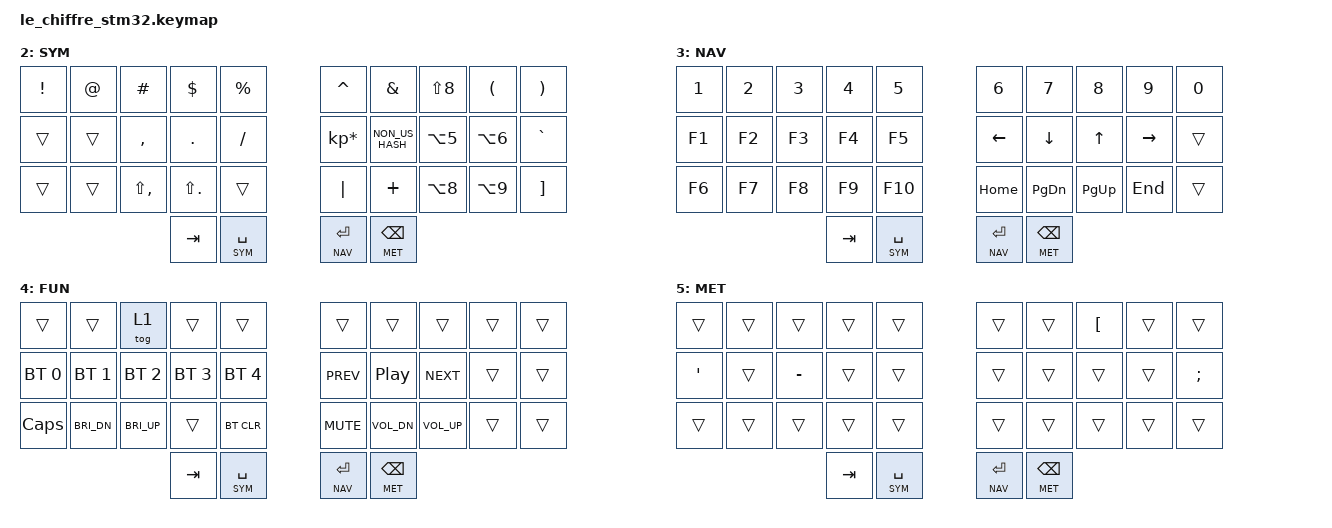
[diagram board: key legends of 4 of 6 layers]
/*
 * Copyright (c) 2020 The ZMK Contributors
 *
 * SPDX-License-Identifier: MIT
 */

#include <behaviors.dtsi>
#include <dt-bindings/zmk/keys.h>
#include <dt-bindings/zmk/bt.h>
#include <dt-bindings/zmk/outputs.h>


#define BAS 0
#define COL 1
#define SYM 2
#define NAV 3
#define FUN 4
#define MET 5

//&mt {
//  quick-tap-ms = <100>;
//  global-quick-tap;
//  flavor = "tap-preferred";
//  tapping-term-ms = <170>;
//};
&mt {
    flavor = "hold-preferred";
    tapping-term-ms = <150>;
};

&lt {
    flavor = "balanced";
    tapping-term-ms = <150>;
};

/ {
    behaviors {
        rot_kp: sensor_rotate_kp {
            compatible = "zmk,behavior-sensor-rotate-var";
            #sensor-binding-cells = <2>;
            bindings = <&kp>, <&kp>;
        };

        am: alpha_mods {
            compatible = "zmk,behavior-hold-tap";
            label = "ALPHA_MT";
            #binding-cells = <2>;
            tapping-term-ms = <200>;
            quick-tap-ms = <150>;
            flavor = "balanced";
            bindings = <&kp>, <&kp>;
        };
        as: alpha_shift {
            compatible = "zmk,behavior-hold-tap";
            label = "ALPHA_SFT";
            #binding-cells = <2>;
            tapping-term-ms = <200>;
            quick-tap-ms = <150>;
            flavor = "balanced";
            bindings = <&kp>, <&kp>;
        };

        // Easy alt-tab with alt+backspace thumb using mod-morphs
        bstab: backspace_tab {
            compatible = "zmk,behavior-mod-morph";
            label = "BSPC_TAB";
            #binding-cells = <0>;
            bindings = <&kp BSPC>, <&kp TAB>;
            mods = <LALT>;
        };
        lt_bspc: layer_tap_backspace_tab {
            compatible = "zmk,behavior-hold-tap";
            label = "LT_BT";
            #binding-cells = <2>;
            tapping-term-ms = <150>;
            flavor = "balanced";
            bindings = <&mo>, <&bstab>;
        };
    };

    cond_layers {
        compatible = "zmk,conditional-layers";
        // Define FUN layer as tri-state
        func_tristate {
            if-layers = <NAV SYM>;
            then-layer = <FUN>;
        };
    };

    combos {
        compatible = "zmk,combos";
        combo_esc {
            timeout-ms = <40>;
            key-positions = <1 2>;
            bindings = <&kp ESC>;
        };
        combo_dot {
            timeout-ms = <40>;
            key-positions = <12 13>;
            bindings = <&kp DOT>;
        };
        combo_comma {
            timeout-ms = <40>;
            key-positions = <11 12>;
            bindings = <&kp COMMA>;
        };
        
    };



    keymap {
        compatible = "zmk,keymap";
// ▄▄▄▄▄▄▄▄▄▄▄▄▄▄▄▄▄▄▄▄▄▄▄▄▄▄▄▄▄▄▄▄▄▄▄▄▄▄▄▄▄▄▄▄▄▄▄▄▄▄▄▄▄▄▄▄▄▄▄▄▄▄▄▄▄▄▄▄▄▄▄▄▄▄▄▄▄▄▄▄▄▄▄▄▄▄▄▄▄▄▄▄▄▄▄▄▄▄▄▄▄▄▄▄▄▄▄▄▄▄▄▄▄▄▄▄▄▄▄▄▄▄▄▄▄
        base {
            // ┏━━━━━━━━━━━━━━━━━━━━━━━━━━━━━━━━━━━━━━━┓
            label= "BAS"                              ;
            // ┗━━━━━━━━━━━━━━━━━━━━━━━━━━━━━━━━━━━━━━━┛
            bindings = <
                    // ╭─────────────┬─────────────┬─────────────┬─────────────┬─────────────╮   ╭─────────────┬─────────────┬─────────────┬─────────────┬─────────────╮
                            &kp X             &kp J      &kp O         &kp V        &kp Z             &kp MINUS    &kp G        &kp C         &kp L          &kp Y         
                    // ├─────────────┼─────────────┼─────────────┼─────────────┼─────────────┤   ├─────────────┼─────────────┼─────────────┼─────────────┼─────────────┤
                        &am LCTRL H   &am LGUI A    &am LALT E    &as LSHFT I   &kp U             &kp D          &as RSHFT T   &am RALT R   &am RGUI N    &am RCTRL S   
                    // ├─────────────┼─────────────┼─────────────┼─────────────┼─────────────┤   ├─────────────┼─────────────┼─────────────┼─────────────┼─────────────┤
                        &kp K         &kp Q         &kp SQT        &kp LBKT       &kp SEMI         &kp B          &kp P        &kp W           &kp M       &kp F      
                    // ╰─────────────┴─────────────┴─────────────┼─────────────┼─────────────┤   ├─────────────┼─────────────┼─────────────┴─────────────┴─────────────╯
                                                                &kp TAB       &lt SYM SPACE     &lt NAV RET   &lt MET BSPC
                    //                                           ╰─────────────┴─────────────╯   ╰─────────────┴─────────────╯
                                                                                            &kp C_PP

            >;          
            sensor-bindings = <&rot_kp C_VOL_UP C_VOL_DN>;
        };
        colemakdh {
            // ┏━━━━━━━━━━━━━━━━━━━━━━━━━━━━━━━━━━━━━━━┓
            label= "COL"                              ;
            // ┗━━━━━━━━━━━━━━━━━━━━━━━━━━━━━━━━━━━━━━━┛

            bindings = <
                // ╭─────────────┬─────────────┬─────────────┬─────────────┬─────────────╮   ╭─────────────┬─────────────┬─────────────┬─────────────┬─────────────╮
                        &kp Q        &kp W          &kp F        &kp P          &kp B              &kp J          &kp L        &kp U         &kp Y        &kp LS(COMMA)
                // ├─────────────┼─────────────┼─────────────┼─────────────┼─────────────┤   ├─────────────┼─────────────┼─────────────┼─────────────┼─────────────┤
                    &am LCTRL A   &am LGUI R    &am LALT S    &as LSHFT T   &kp G             &kp M          &as RSHFT N   &am RALT E   &am RGUI I    &am RCTRL O   
                // ├─────────────┼─────────────┼─────────────┼─────────────┼─────────────┤   ├─────────────┼─────────────┼─────────────┼─────────────┼─────────────┤
                        &kp Z         &kp X          &kp C          &kp D        &kp V            &kp K          &kp H       &kp COMMA    &kp PERIOD     &kp LS(N7)
                // ╰─────────────┴─────────────┴─────────────┼─────────────┼─────────────┤   ├─────────────┼─────────────┼─────────────┴─────────────┴─────────────╯
                                                            &kp TAB       &lt SYM SPACE     &lt NAV RET   &lt MET BSPC
                //                                           ╰─────────────┴─────────────╯   ╰─────────────┴─────────────╯
                                                                                        &kp C_PP


            >;               
            sensor-bindings = <&rot_kp C_VOL_UP C_VOL_DN>;
        };

        symbol_layer {
        // -----------------------------------------------------------------------------------------
        //  |  !  |  "  |  §  |  $  |  %  |   |  & |  /  |  (  |  )  |  =  |   
        //  |     |     |     |     |     |   |  * |  #  |  [  |  ]   |  <  |  
        //  |     |     |     |     |     |   | '  |  `  |  {  |  }   |  +  | 
        //         TAB | SYM / SPC  |            | NAV / ENT | MET / BKSP  
            label = "SYM";
            bindings = <
                // ╭─────────────┬─────────────┬─────────────┬─────────────┬─────────────╮   ╭─────────────┬─────────────┬─────────────┬─────────────┬─────────────╮
                        &kp EXCL      &kp AT        &kp HASH      &kp DLLR      &kp PRCNT         &kp CARET     &kp AMPS      &kp LS(N8)     &kp LPAR     &kp RPAR       
                // ├─────────────┼─────────────┼─────────────┼─────────────┼─────────────┤   ├─────────────┼─────────────┼─────────────┼─────────────┼─────────────┤
                        &trans        &trans        &kp COMMA        &kp DOT     &kp FSLH            &kp KP_MULTIPLY &kp NON_US_HASH &kp LA(N5) &kp LA(N6)  &kp GRAVE      
                // ├─────────────┼─────────────┼─────────────┼─────────────┼─────────────┤   ├─────────────┼─────────────┼─────────────┼─────────────┼─────────────┤
                        &trans        &trans        &kp LS(COMMA)     &kp LS(DOT)                &trans            &kp PIPE      &kp PLUS      &kp LA(N8)    &kp LA(N9)    &kp RBKT      
                // ╰─────────────┴─────────────┴─────────────┼─────────────┼─────────────┤   ├─────────────┼─────────────┼─────────────┴─────────────┴─────────────╯
                                                            &kp TAB       &lt SYM SPACE     &lt NAV RET   &lt MET BSPC
                //                                           ╰─────────────┴─────────────╯   ╰─────────────┴─────────────╯
            >;
        };

       navigation_layer {
        // -----------------------------------------------------------------------------------------
        // | |  1  |  2  |  3  |  4  |  5  |   |  6   |  7  | 8   |  9  |  0  |      |
        // | | F1  | F2  | F3  | F4  | F5  |   | LFT  | DWN | UP  | RGT |     |      |
        // | | F6  | F7  | F8  | F9  | F10 |   | home | PDN | PUP | END |     |      |
        //        | ESC | TAB | SYM / SPC  |            | NAV / ENT | MET / BKSP  | DEL |
            label = "NAV";
            bindings = <
                // ╭─────────────┬─────────────┬─────────────┬─────────────┬─────────────╮   ╭─────────────┬─────────────┬─────────────┬─────────────┬─────────────╮
                        &kp N1        &kp N2        &kp N3        &kp N4         &kp N5           &kp N6        &kp N7        &kp N8        &kp N9         &kp N0       
                // ├─────────────┼─────────────┼─────────────┼─────────────┼─────────────┤   ├─────────────┼─────────────┼─────────────┼─────────────┼─────────────┤
                        &kp F1        &kp F2        &kp F3        &kp F4        &kp F5            &kp LEFT      &kp DOWN      &kp UP        &kp RIGHT     &trans        
                // ├─────────────┼─────────────┼─────────────┼─────────────┼─────────────┤   ├─────────────┼─────────────┼─────────────┼─────────────┼─────────────┤
                            &kp F6        &kp F7        &kp F8        &kp F9        &kp F10           &kp HOME      &kp PG_DN     &kp PG_UP     &kp END       &trans        
                // ╰─────────────┴─────────────┴─────────────┼─────────────┼─────────────┤   ├─────────────┼─────────────┼─────────────┼─────────────┴─────────────╯
                                                                            &kp TAB       &lt SYM SPACE     &lt NAV RET   &lt MET BSPC  
                //                                                          ╰─────────────┴─────────────╯   ╰─────────────┴─────────────╯
            >;
        };

        function_layer {
            label = "FUN";
            bindings = <
                // ╭─────────────┬─────────────┬─────────────┬─────────────┬─────────────╮   ╭─────────────┬─────────────┬─────────────┬─────────────┬─────────────╮
                    &trans        &trans          &tog 1         &trans        &trans         &trans           &trans        &trans       &trans        &trans        
                // ├─────────────┼─────────────┼─────────────┼─────────────┼─────────────┤   ├─────────────┼─────────────┼─────────────┼─────────────┼─────────────┤
                    &bt BT_SEL 0  &bt BT_SEL 1  &bt BT_SEL 2  &bt BT_SEL 3  &bt BT_SEL 4      &kp C_PREV       &kp C_PP      &kp C_NEXT  &trans        &trans        
                // ├─────────────┼─────────────┼─────────────┼─────────────┼─────────────┤   ├─────────────┼─────────────┼─────────────┼─────────────┼─────────────┤
                    &kp CAPS      &kp C_BRI_DN  &kp C_BRI_UP  &trans        &bt BT_CLR        &kp C_MUTE       &kp C_VOL_DN &kp C_VOL_UP    &trans        &trans        
                // ╰─────────────┴─────────────┴─────────────┼─────────────┼─────────────┤   ├─────────────┼─────────────┼─────────────┼─────────────┴─────────────╯
                                                            &kp TAB       &lt SYM SPACE        &lt NAV RET   &lt MET BSPC  
                //                                           ╰─────────────┴─────────────╯   ╰─────────────┴─────────────╯
            >;
        };
        metall_layer {
            label = "MET";
            bindings = <
                // ╭─────────────┬─────────────┬─────────────┬─────────────┬─────────────╮   ╭─────────────┬─────────────┬─────────────┬─────────────┬─────────────╮
                            &trans        &trans        &trans        &trans        &trans       &trans        &trans        &kp LBKT      &trans        &trans        
                // ├─────────────┼─────────────┼─────────────┼─────────────┼─────────────┤   ├─────────────┼─────────────┼─────────────┼─────────────┼─────────────┤
                    &kp SQT        &trans        &kp MINUS        &trans        &trans              &trans        &trans        &trans        &trans        &kp SEMI        
                // ├─────────────┼─────────────┼─────────────┼─────────────┼─────────────┤   ├─────────────┼─────────────┼─────────────┼─────────────┼─────────────┤
                        &trans        &trans        &trans        &trans        &trans              &trans        &trans        &trans        &trans        &trans        
                // ╰─────────────┴─────────────┴─────────────┼─────────────┼─────────────┤   ├─────────────┼─────────────┼─────────────┼─────────────┴─────────────╯
                                                                            &kp TAB       &lt SYM SPACE     &lt NAV RET   &lt MET BSPC  
                //                                                          ╰─────────────┴─────────────╯   ╰─────────────┴─────────────╯
            >;
        };
              
    };
};
